# SC32F10T_10G register map
File version: 1.0
CPU: CM0+ r0p1, little endian, MPU, no FPU, 4 interrupt priority bits
Registers are 32-bit, read-write, reset 0x0 unless marked. A register's access mark holds for its fields unless they carry their own. Offsets are from the block's base; [hi:lo] are bit positions; 'fields as' and 'values as' point back to an identical list.

## TIM2
Base 0x40020180
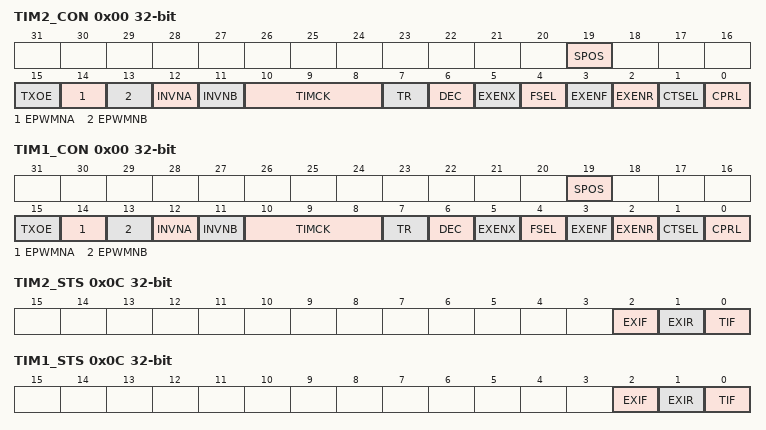
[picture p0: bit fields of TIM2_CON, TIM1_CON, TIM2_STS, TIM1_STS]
0x00 TIM2_CON — 定时器控制寄存器
  [19] SPOS — TIM2管脚映射控制位@ TIM2_CON 信号SPOS值T2CAP/T2SPOS=0PA10SPOS=1PA12TIM3管脚映射控制位@ TIM3_CON 信号SPOS值T3CAP/T3SPOS=0PA0SPOS=1PA13TIM7管脚映射控制位@ TIM7
  [15] TXOE — Tn引脚信号方向控制位0：Tn作为时钟输入口或I/O 端口1：Tn用于可编程时钟输出
  [14] EPWMNA — Tn_PWMA所在管脚 PWM波形输出使能位0：关闭1：使能
  [13] EPWMNB — TnEX_PWMB所在管脚 PWM波形输出使能位0：关闭1：使能
  [12] INVNA — TPWMnA波形输出反向控制位0：正常1：波形输出反向
  [11] INVNB — TPWMnB波形输出反向控制位0：正常1：波形输出反向
  [10:8] TIMCK — TIM时钟频率档位控制位000：fTIM/1001：fTIM/2010：fTIM/4011：fTIM/8100：fTIM/16101：fTIM/32110：fTIM/64111：fTIM/128fTIM对应的时钟可能为fPCLK 或Tn输入
  [7] TR — TIMn开始/停止控制位，n=0~7 0：停止TIMn / TPWMn计数器 1：开始TIMn / TPWMn计数器
  [6] DEC — 递增/递减方向控制位 0：TIMn为递增的定时/计数器 1：TIMn作为递增/递减的定时/计数器，TnEX用来选择计数方向
  [5] EXENX — TnEX设置位，n=0该位在不同模式下作用不同：重载模式：（CPRL = 0） 该位用于控制TnEX引脚上的外部事件输入(下降沿)，用作重载允许/禁止控制： 0：忽略TnEX引脚上的事件 1：检测到TnEX引脚上一个下降沿，产生一个重载捕获模式：（CPRL = 1） 该位用作TnEX下降沿信号捕获选通位： 0：忽略TnEX引脚上的事件 1：当FSEL = 1，检测到TnEX引脚上一个下降沿，产生一
  [4] FSEL — 下降沿信号选择位该位仅在捕获模式（CPRL=1)下有效 0：检测到Tn引脚上一个下降沿，产生一个捕获。忽略TnEX引脚上的事件 1：检测到TnEX引脚上一个下降沿，产生一个捕获。忽略Tn引脚上的事件
  [3] EXENF — 下降沿信号捕获使能位:0：忽略Tn引脚上的事件 1：检测到Tn引脚上一个下降沿，产生一个捕获，EXIF被置起，TnCNT寄存器的值捕获到寄存器FCAP里
  [2] EXENR — Tn引脚上的上升沿信号捕获使能位 0：忽略Tn引脚上的事件 1：检测到Tn引脚上一个上升沿，产生一个捕获，EXIR被置起，TnCNT寄存器的值捕获到寄存器RCAP里
  [1] CTSEL — 定时器/计数器选定位 0：定时器方式 1：计数器方式
  [0] CPRL — 捕获/重载方式设置位 0：重载功能 1：捕获功能
0x00 TIM1_CON — 定时器控制寄存器
  fields as TIM2_CON
0x04 TIM2_CNT — 定时器计数值寄存器
  [15:0] CNT — TIMn计数值
0x04 TIM1_CNT — 定时器计数值寄存器
  [15:0] CNT — TIMn计数值
0x08 TIM2_RLD — 定时器重载寄存器
  [15:0] RLD — 定时器溢出或在外部输入TnEX上的下降沿都能触发一个16位重载。产生重载时，定时器自动将用户软件写好的RLD[15:0]值装入TnCNT寄存器。
0x08 TIM1_RLD — 定时器重载寄存器
  fields as TIM2_RLD
0x0C TIM2_STS — 定时标志位寄存器
  [2] EXIF — 外部事件输入下降沿被检测到的标志位该位由硬件置1，通过软件写1清0。 0：无外部事件输入 1：检测到外部输入(如果EXENF = 1，由硬件设1) 注意：捕获模式下，该位软件清0之前不允许更新TnFCAP值
  [1] EXIR — Tn引脚外部事件输入上升沿被检测到的标志位该位由硬件置1，通过软件写1清0。 0：无外部事件输入 1：检测到外部输入(如果EXENR = 1，由硬件设1) 注意：捕获模式下，该位软件清0之前不允许更新TnRCAP值
  [0] TIF — 定时器溢出标志位该位由硬件置1，通过软件写1清0。 0：无溢出(必须由软件清0) 1：溢出(如果RCLK = 0和TCLK = 0，由硬件设1)
0x0C TIM1_STS — 定时标志位寄存器
  fields as TIM2_STS
0x10 TIM2_PDTA — TnPWMA占空比设定寄存器（@CPRL = 0）
  [15:0] PDT — TPWMnA 占空比寄存器，n=1~7TPWMnA的波形的高电平宽度是PDT[15:0]个TIM时钟
0x10 TIM1_PDTA — TnPWMA占空比设定寄存器（@CPRL = 0）
  [15:0] PDT — TPWMnA 占空比寄存器，n=1~7TPWMnA的波形的高电平宽度是PDT[15:0]个TIM时钟
0x14 TIM2_FCAP — 下降沿数据捕获寄存器（@CPRL = 1）
  [15:0] FCAP — TIMn的PWM捕获模式下，当下降沿捕获条件发生，CNT计数器值将被保存到该寄存器。
0x14 TIM1_FCAP — 下降沿数据捕获寄存器（@CPRL = 1）
  [15:0] FCAP — TIMn的PWM捕获模式下，当下降沿捕获条件发生，CNT计数器值将被保存到该寄存器。
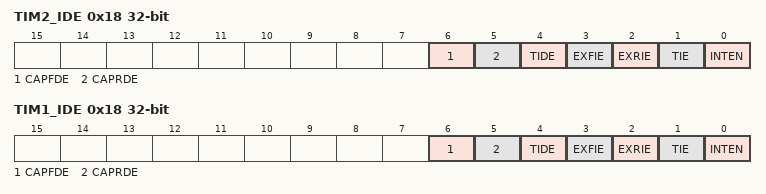
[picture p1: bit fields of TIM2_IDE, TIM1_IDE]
0x18 TIM2_IDE — TIMn的中断使能及DMA控制寄存器
  [6] CAPFDE — 下降沿捕获事件触发DMA请求使能位 0：下降沿捕获事件禁止产生DMA请求 1：产生新的下降沿捕获时，触发DMA请求，DMA搬运FCAP寄存器的值
  [5] CAPRDE — 上升沿捕获事件触发DMA请求使能位 0：上升沿捕获事件禁止产生DMA请求 1：产生新的下降沿捕获时，触发DMA请求，DMA搬运RCAP寄存器的值
  [4] TIDE — 定时器溢出事件触发DMA请求使能位 0：定时器溢出禁止产生DMA请求 1：定时器溢出允许产生DMA请求
  [3] EXFIE — 外部事件输入下降沿中断开关 0：禁止下降沿中断 1：使能下降沿中断
  [2] EXRIE — 外部事件输入上升沿中断开关 0：禁止上升沿中断 1：使能上升沿中断
  [1] TIE — 定时器溢出中断开关 0：禁止溢出中断 1：使能溢出中断
  [0] INTEN — 中断请求 CPU的使能控制位0：禁止中断请求1：使能中断请求
0x18 TIM1_IDE — TIMn的中断使能及DMA控制寄存器
  fields as TIM2_IDE

## TIM3
Base 0x400201C0
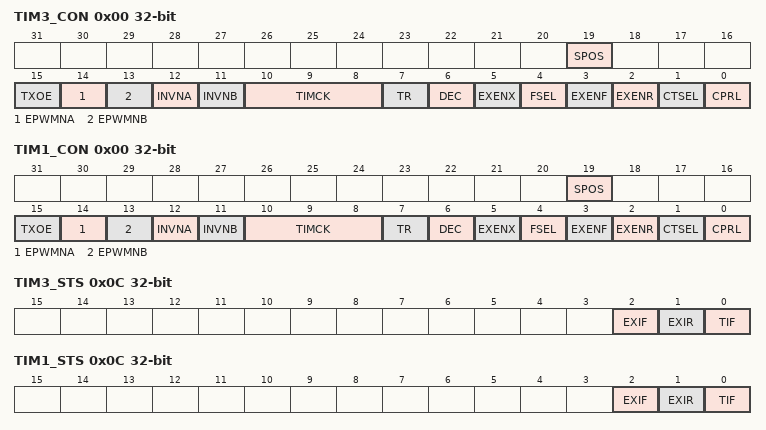
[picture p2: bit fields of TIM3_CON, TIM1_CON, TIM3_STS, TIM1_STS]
0x00 TIM3_CON — 定时器控制寄存器
  [19] SPOS — TIM2管脚映射控制位@ TIM2_CON 信号SPOS值T2CAP/T2SPOS=0PA10SPOS=1PA12TIM3管脚映射控制位@ TIM3_CON 信号SPOS值T3CAP/T3SPOS=0PA0SPOS=1PA13TIM7管脚映射控制位@ TIM7
  [15] TXOE — Tn引脚信号方向控制位0：Tn作为时钟输入口或I/O 端口1：Tn用于可编程时钟输出
  [14] EPWMNA — Tn_PWMA所在管脚 PWM波形输出使能位0：关闭1：使能
  [13] EPWMNB — TnEX_PWMB所在管脚 PWM波形输出使能位0：关闭1：使能
  [12] INVNA — TPWMnA波形输出反向控制位0：正常1：波形输出反向
  [11] INVNB — TPWMnB波形输出反向控制位0：正常1：波形输出反向
  [10:8] TIMCK — TIM时钟频率档位控制位000：fTIM/1001：fTIM/2010：fTIM/4011：fTIM/8100：fTIM/16101：fTIM/32110：fTIM/64111：fTIM/128fTIM对应的时钟可能为fPCLK 或Tn输入
  [7] TR — TIMn开始/停止控制位，n=0~7 0：停止TIMn / TPWMn计数器 1：开始TIMn / TPWMn计数器
  [6] DEC — 递增/递减方向控制位 0：TIMn为递增的定时/计数器 1：TIMn作为递增/递减的定时/计数器，TnEX用来选择计数方向
  [5] EXENX — TnEX设置位，n=0该位在不同模式下作用不同：重载模式：（CPRL = 0） 该位用于控制TnEX引脚上的外部事件输入(下降沿)，用作重载允许/禁止控制： 0：忽略TnEX引脚上的事件 1：检测到TnEX引脚上一个下降沿，产生一个重载捕获模式：（CPRL = 1） 该位用作TnEX下降沿信号捕获选通位： 0：忽略TnEX引脚上的事件 1：当FSEL = 1，检测到TnEX引脚上一个下降沿，产生一
  [4] FSEL — 下降沿信号选择位该位仅在捕获模式（CPRL=1)下有效 0：检测到Tn引脚上一个下降沿，产生一个捕获。忽略TnEX引脚上的事件 1：检测到TnEX引脚上一个下降沿，产生一个捕获。忽略Tn引脚上的事件
  [3] EXENF — 下降沿信号捕获使能位:0：忽略Tn引脚上的事件 1：检测到Tn引脚上一个下降沿，产生一个捕获，EXIF被置起，TnCNT寄存器的值捕获到寄存器FCAP里
  [2] EXENR — Tn引脚上的上升沿信号捕获使能位 0：忽略Tn引脚上的事件 1：检测到Tn引脚上一个上升沿，产生一个捕获，EXIR被置起，TnCNT寄存器的值捕获到寄存器RCAP里
  [1] CTSEL — 定时器/计数器选定位 0：定时器方式 1：计数器方式
  [0] CPRL — 捕获/重载方式设置位 0：重载功能 1：捕获功能
0x00 TIM1_CON — 定时器控制寄存器
  fields as TIM3_CON
0x04 TIM3_CNT — 定时器计数值寄存器
  [15:0] CNT — TIMn计数值
0x04 TIM1_CNT — 定时器计数值寄存器
  [15:0] CNT — TIMn计数值
0x08 TIM3_RLD — 定时器重载寄存器
  [15:0] RLD — 定时器溢出或在外部输入TnEX上的下降沿都能触发一个16位重载。产生重载时，定时器自动将用户软件写好的RLD[15:0]值装入TnCNT寄存器。
0x08 TIM1_RLD — 定时器重载寄存器
  fields as TIM3_RLD
0x0C TIM3_STS — 定时标志位寄存器
  [2] EXIF — 外部事件输入下降沿被检测到的标志位该位由硬件置1，通过软件写1清0。 0：无外部事件输入 1：检测到外部输入(如果EXENF = 1，由硬件设1) 注意：捕获模式下，该位软件清0之前不允许更新TnFCAP值
  [1] EXIR — Tn引脚外部事件输入上升沿被检测到的标志位该位由硬件置1，通过软件写1清0。 0：无外部事件输入 1：检测到外部输入(如果EXENR = 1，由硬件设1) 注意：捕获模式下，该位软件清0之前不允许更新TnRCAP值
  [0] TIF — 定时器溢出标志位该位由硬件置1，通过软件写1清0。 0：无溢出(必须由软件清0) 1：溢出(如果RCLK = 0和TCLK = 0，由硬件设1)
0x0C TIM1_STS — 定时标志位寄存器
  fields as TIM3_STS
0x10 TIM3_PDTA — TnPWMA占空比设定寄存器（@CPRL = 0）
  [15:0] PDT — TPWMnA 占空比寄存器，n=1~7TPWMnA的波形的高电平宽度是PDT[15:0]个TIM时钟
0x10 TIM1_PDTA — TnPWMA占空比设定寄存器（@CPRL = 0）
  [15:0] PDT — TPWMnA 占空比寄存器，n=1~7TPWMnA的波形的高电平宽度是PDT[15:0]个TIM时钟
0x14 TIM3_FCAP — 下降沿数据捕获寄存器（@CPRL = 1）
  [15:0] FCAP — TIMn的PWM捕获模式下，当下降沿捕获条件发生，CNT计数器值将被保存到该寄存器。
0x14 TIM1_FCAP — 下降沿数据捕获寄存器（@CPRL = 1）
  [15:0] FCAP — TIMn的PWM捕获模式下，当下降沿捕获条件发生，CNT计数器值将被保存到该寄存器。
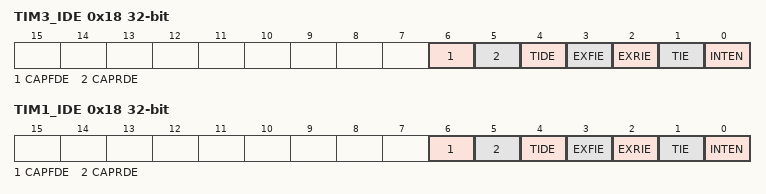
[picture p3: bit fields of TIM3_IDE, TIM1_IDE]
0x18 TIM3_IDE — TIMn的中断使能及DMA控制寄存器
  [6] CAPFDE — 下降沿捕获事件触发DMA请求使能位 0：下降沿捕获事件禁止产生DMA请求 1：产生新的下降沿捕获时，触发DMA请求，DMA搬运FCAP寄存器的值
  [5] CAPRDE — 上升沿捕获事件触发DMA请求使能位 0：上升沿捕获事件禁止产生DMA请求 1：产生新的下降沿捕获时，触发DMA请求，DMA搬运RCAP寄存器的值
  [4] TIDE — 定时器溢出事件触发DMA请求使能位 0：定时器溢出禁止产生DMA请求 1：定时器溢出允许产生DMA请求
  [3] EXFIE — 外部事件输入下降沿中断开关 0：禁止下降沿中断 1：使能下降沿中断
  [2] EXRIE — 外部事件输入上升沿中断开关 0：禁止上升沿中断 1：使能上升沿中断
  [1] TIE — 定时器溢出中断开关 0：禁止溢出中断 1：使能溢出中断
  [0] INTEN — 中断请求 CPU的使能控制位0：禁止中断请求1：使能中断请求
0x18 TIM1_IDE — TIMn的中断使能及DMA控制寄存器
  fields as TIM3_IDE
